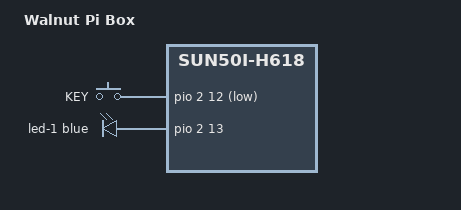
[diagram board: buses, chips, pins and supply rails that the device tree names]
// SPDX-License-Identifier: (GPL-2.0+ OR MIT)
/*
 * Walnut Pi Box: Walnut Pi CM1 on the Box IO carrier.
 * Full-size HDMI, 100 Mbit Ethernet, 2x USB 2.0 host, 3.5mm audio,
 * IR receiver, 40-pin header (peripherals via overlays), OLED header
 * (I2C, via overlay), USB-C 5V power input (power only).
 */

/dts-v1/;

#include "sun50i-h618-walnutpi-cm1.dtsi"

#include <dt-bindings/input/linux-event-codes.h>

/ {
	model = "Walnut Pi Box";
	compatible = "walnutpi,walnutpi-box", "allwinner,sun50i-h618";

	gpio-keys-polled {
		compatible = "gpio-keys-polled";
		poll-interval = <100>;

		key-user {
			label = "KEY";
			linux,code = <KEY_PROG1>;
			gpios = <&pio 2 12 GPIO_ACTIVE_LOW>; /* PC12 */
		};
	};

	leds {
		/* carrier LED, next to the module's PC7 status LED */
		led-1 {
			function = LED_FUNCTION_ACTIVITY;
			color = <LED_COLOR_ID_BLUE>;
			gpios = <&pio 2 13 GPIO_ACTIVE_HIGH>; /* PC13 */
			linux,default-trigger = "heartbeat";
		};
	};
};

/* USB1 is not routed on the Box IO carrier */
&ehci1 {
	status = "disabled";
};

&hdmi_connector {
	type = "a";
};

&ohci1 {
	status = "disabled";
};
